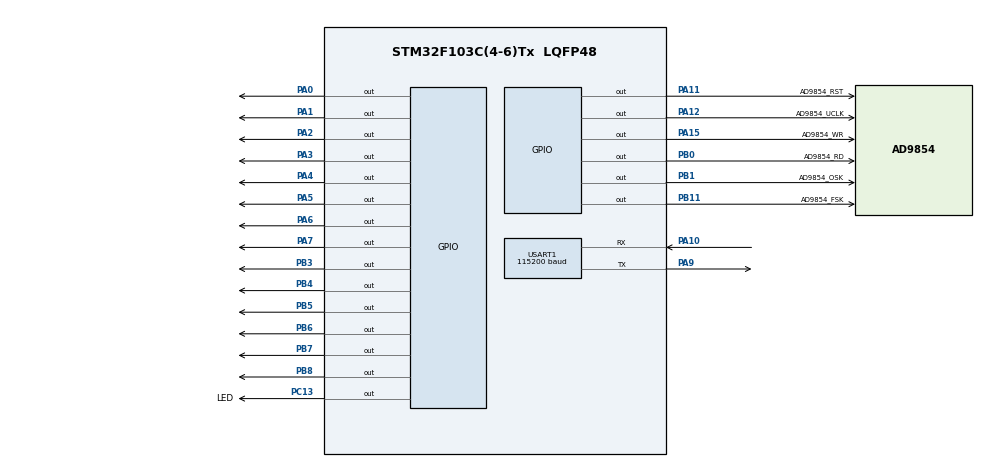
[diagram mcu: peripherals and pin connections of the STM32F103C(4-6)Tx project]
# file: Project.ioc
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Mcu.Family=STM32F1
Mcu.Name=STM32F103C(4-6)Tx
Mcu.Package=LQFP48
NVIC.PriorityGroup=NVIC_PRIORITYGROUP_2
NVIC.TIM1_UP_IRQn=true\:2\:2\:true\:false\:true\:true\:true\:true
NVIC.USART1_IRQn=true\:3\:3\:true\:false\:true\:true\:true\:true
PA0-WKUP.Signal=GPIO_Output
PA1.Signal=GPIO_Output
PA10.Mode=Asynchronous
PA10.Signal=USART1_RX
PA11.GPIO_Label=AD9854_RST
PA11.Signal=GPIO_Output
PA12.GPIO_Label=AD9854_UCLK
PA12.Signal=GPIO_Output
PA13.Mode=Serial_Wire
PA13.Signal=SYS_JTMS-SWDIO
PA14.Mode=Serial_Wire
PA14.Signal=SYS_JTCK-SWCLK
PA15.GPIO_Label=AD9854_WR
PA15.Signal=GPIO_Output
PA2.Signal=GPIO_Output
PA3.Signal=GPIO_Output
PA4.Signal=GPIO_Output
PA5.Signal=GPIO_Output
PA6.Signal=GPIO_Output
PA7.Signal=GPIO_Output
PA9.Mode=Asynchronous
PA9.Signal=USART1_TX
PB0.GPIO_Label=AD9854_RD
PB0.Signal=GPIO_Output
PB1.GPIO_Label=AD9854_OSK
PB1.Signal=GPIO_Output
PB11.GPIO_Label=AD9854_FSK
PB11.Signal=GPIO_Output
PB3.Signal=GPIO_Output
PB4.Signal=GPIO_Output
PB5.Signal=GPIO_Output
PB6.Signal=GPIO_Output
PB7.Signal=GPIO_Output
PB8.Signal=GPIO_Output
PC13-TAMPER-RTC.GPIO_Label=LED
PC13-TAMPER-RTC.PinState=GPIO_PIN_RESET
PC13-TAMPER-RTC.Signal=GPIO_Output
PD0-OSC_IN.Mode=HSE-External-Oscillator
PD0-OSC_IN.Signal=RCC_OSC_IN
PD1-OSC_OUT.Mode=HSE-External-Oscillator
PD1-OSC_OUT.Signal=RCC_OSC_OUT
ProjectManager.HeapSize=0x200
ProjectManager.StackSize=0x400
ProjectManager.TargetToolchain=MDK-ARM V5.32
RCC.AHBFreq_Value=72000000
RCC.APB1CLKDivider=RCC_HCLK_DIV2
RCC.APB1Freq_Value=36000000
RCC.APB1TimFreq_Value=72000000
RCC.APB2Freq_Value=72000000
RCC.APB2TimFreq_Value=72000000
RCC.HCLKFreq_Value=72000000
RCC.PLLMUL=RCC_PLL_MUL9
RCC.PLLSourceVirtual=RCC_PLLSOURCE_HSE
RCC.SYSCLKFreq_VALUE=72000000
RCC.SYSCLKSource=RCC_SYSCLKSOURCE_PLLCLK
RCC.USBFreq_Value=72000000
USART1.BaudRate=115200
USART1.VirtualMode=VM_ASYNC
VP_TIM1_VS_ClockSourceINT.Mode=Internal
board=custom

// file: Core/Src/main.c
/* USER CODE BEGIN Header */
/**
  ******************************************************************************
  * @file           : main.c
  * @brief          : Main program body
  ******************************************************************************
  * @attention
  *
  * Copyright (c) 2023 STMicroelectronics.
  * All rights reserved.
  *
  * This software is licensed under terms that can be found in the LICENSE file
  * in the root directory of this software component.
  * If no LICENSE file comes with this software, it is provided AS-IS.
  *
  ******************************************************************************
  */
/* USER CODE END Header */
#include "main.h"
#include "tim.h"
#include "usart.h"
#include "gpio.h"

/* USER CODE BEGIN Includes */
#include "Led.h"
#include "Usart1.h"
#include "AD9854.h"

/* USER CODE END Includes */

void SystemClock_Config(void);

int main(void)
{
  /* USER CODE BEGIN 1 */
	struct Uart_Data_Struc Uart_Data_AD9854;
  /* USER CODE END 1 */

  /* MCU Configuration--------------------------------------------------------*/

  /* Reset of all peripherals, Initializes the Flash interface and the Systick. */
  LL_APB2_GRP1_EnableClock(LL_APB2_GRP1_PERIPH_AFIO);
  LL_APB1_GRP1_EnableClock(LL_APB1_GRP1_PERIPH_PWR);

  /* System interrupt init*/
  NVIC_SetPriorityGrouping(NVIC_PRIORITYGROUP_2);

  /* SysTick_IRQn interrupt configuration */
  NVIC_SetPriority(SysTick_IRQn, NVIC_EncodePriority(NVIC_GetPriorityGrouping(),1, 1));

  /** NOJTAG: JTAG-DP Disabled and SW-DP Enabled
  */
  LL_GPIO_AF_Remap_SWJ_NOJTAG();

  /* Configure the system clock */
  SystemClock_Config();

  /* Initialize all configured peripherals */
  MX_GPIO_Init();
  MX_TIM1_Init();
  MX_USART1_UART_Init();
  /* USER CODE BEGIN 2 */
	AD9854_Init();                //AD9854配置初始化
	AD9854_SetSine(1000000,4095);      //默认输出1MHz满幅正弦波
  /* USER CODE END 2 */

  /* Infinite loop */
  /* USER CODE BEGIN WHILE */
  while (1)
  {
		if(AD9854_Uartdata_Analysis(&Uart_Data_AD9854)!=0)           //AD9854的串口接收数据提取
		{
			USART1_Printf("Error\r\n");
		}
		USART1_Recv_DataArray_Clear();                          //清空串口缓冲区数据
		AD9854_Cmd_Execute(&Uart_Data_AD9854);                  //根据接收到的数据执行对应命令
		LED_Toggle();
		LL_mDelay(1000);
    /* USER CODE END WHILE */

  }
}

void SystemClock_Config(void)
{
  LL_FLASH_SetLatency(LL_FLASH_LATENCY_2);
  while(LL_FLASH_GetLatency()!= LL_FLASH_LATENCY_2)
  {
  }
  LL_RCC_HSE_Enable();

   /* Wait till HSE is ready */
  while(LL_RCC_HSE_IsReady() != 1)
  {

  }
  LL_RCC_PLL_ConfigDomain_SYS(LL_RCC_PLLSOURCE_HSE_DIV_1, LL_RCC_PLL_MUL_9);
  LL_RCC_PLL_Enable();

   /* Wait till PLL is ready */
  while(LL_RCC_PLL_IsReady() != 1)
  {

  }
  LL_RCC_SetAHBPrescaler(LL_RCC_SYSCLK_DIV_1);
  LL_RCC_SetAPB1Prescaler(LL_RCC_APB1_DIV_2);
  LL_RCC_SetAPB2Prescaler(LL_RCC_APB2_DIV_1);
  LL_RCC_SetSysClkSource(LL_RCC_SYS_CLKSOURCE_PLL);

   /* Wait till System clock is ready */
  while(LL_RCC_GetSysClkSource() != LL_RCC_SYS_CLKSOURCE_STATUS_PLL)
  {

  }
  LL_Init1msTick(72000000);
  LL_SetSystemCoreClock(72000000);
}

void Error_Handler(void)
{
  __disable_irq();
  while (1)
  {
  }
}
